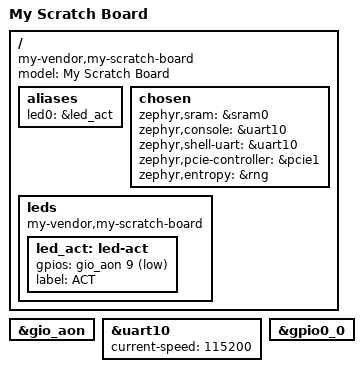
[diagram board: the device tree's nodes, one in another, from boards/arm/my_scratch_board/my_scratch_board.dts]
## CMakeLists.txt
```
cmake_minimum_required(VERSION 3.20)

set(DTS_ROOT ${CMAKE_CURRENT_SOURCE_DIR})
set(KCONFIG_ROOT ${CMAKE_CURRENT_SOURCE_DIR}/Kconfig.app)

find_package(Zephyr REQUIRED HINTS $ENV{ZEPHYR_BASE})
project(led_sensor_task2)

target_include_directories(app PRIVATE drivers/led_sensor)

target_sources(app PRIVATE
    src/main.c
    drivers/led_sensor/led_sensor.c
)
```

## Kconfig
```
source "Kconfig.zephyr"

mainmenu "LED Control Application"

menuconfig LED_SUBSYSTEM
    bool "LED Subsystem"
    default y

if LED_SUBSYSTEM

choice
    prompt "LED blink sleep time"
    default LED_BLINK_SLEEP_1S

    config LED_BLINK_SLEEP_250MS
        bool "250ms (fast)"
    config LED_BLINK_SLEEP_500MS
        bool "500ms (standard)"
    config LED_BLINK_SLEEP_1S
        bool "1s (medium)"
    config LED_BLINK_SLEEP_2S
        bool "2s (slow)"
endchoice

config LED_BLINK_TIME_MS
    int
    default 250 if LED_BLINK_SLEEP_250MS
    default 500 if LED_BLINK_SLEEP_500MS
    default 1000 if LED_BLINK_SLEEP_1S
    default 2000 if LED_BLINK_SLEEP_2S

menuconfig ADVANCED_LED_SETTINGS
    bool "Advanced LED settings"

if ADVANCED_LED_SETTINGS
    config LED_BRIGHTNESS
        int "LED brightness (0-100)"
        range 0 100
        default 100

    config LED_FADE_DURATION
        int "LED fade duration (ms)"
        range 0 5000
        default 500

    menu "Expert settings"
        visible if ADVANCED_LED_SETTINGS
        config ENABLE_LED_DEBUGGING
            bool "Enable LED debugging"
        config CUSTOM_BLINK_PATTERN
            bool "Custom blink pattern"
    endmenu
endif

endif

config APP_HEARTBEAT_PERIOD_MS
    int "Heartbeat LED period in milliseconds"
    default 500
    range 100 2000
    help
        Time between LED toggles (half period).
```

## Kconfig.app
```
source "$(APPLICATION_SOURCE_DIR)/drivers/led_sensor/Kconfig"
source "$(ZEPHYR_BASE)/Kconfig"
```

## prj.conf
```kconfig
CONFIG_MY_LED_SENSOR=y
CONFIG_GPIO=y
CONFIG_LOG=y
CONFIG_CONSOLE=y
CONFIG_SERIAL=y
CONFIG_UART_CONSOLE=y
```

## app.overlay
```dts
/ {
    my_led_sensor: my-led-sensor {
        compatible = "my-vendor,my-led-sensor";
        led-gpios = <&gio_aon 9 GPIO_ACTIVE_LOW>;
        status = "okay";
    };

    aliases {
        my-led-sensor = &my_led_sensor;
    };
};

/* Uses the activity LED on Raspberry Pi 5 (GPIO 9 via gio_aon) */
```

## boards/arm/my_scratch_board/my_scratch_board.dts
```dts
/*
 * Copyright 2024 Junho Lee <junho@tsnlab.com>
 *
 * SPDX-License-Identifier: Apache-2.0
 */

/dts-v1/;

#include <broadcom/bcm2712.dtsi>
#include <zephyr/dt-bindings/gpio/gpio.h>

/ {
	compatible = "my-vendor,my-scratch-board";
	model = "My Scratch Board";
	#address-cells = <2>;
	#size-cells = <1>;

	aliases {
		led0 = &led_act;
	};

	chosen {
		zephyr,sram = &sram0;
		zephyr,console = &uart10;
		zephyr,shell-uart = &uart10;
		zephyr,pcie-controller = &pcie1;
		zephyr,entropy = &rng;
	};

	leds {
		compatible = "my-vendor,my-scratch-board";

		led_act: led-act {
			gpios = <&gio_aon 9 GPIO_ACTIVE_LOW>;
			label = "ACT";
		};
	};
};

&gio_aon {
	status = "okay";
};

&uart10 {
	status = "okay";
	current-speed = <115200>;
};

&gpio0_0 {
	status = "okay";
};
```

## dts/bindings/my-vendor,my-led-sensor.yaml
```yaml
description: Simple on-board LED sensor driver

compatible: "my-vendor,my-led-sensor"

include: [sensor-device.yaml]

properties:
  led-gpios:
    type: phandle-array
    required: true
    description: GPIO pin connected to the LED
```

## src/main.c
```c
#include <zephyr/kernel.h>
#include <zephyr/device.h>
#include <zephyr/logging/log.h>
#include "led_sensor.h"

LOG_MODULE_REGISTER(main, LOG_LEVEL_INF);

int main(void)
{
    printk("=== Zephyr booted Task 2 ===\n");

    const struct device *sensor = DEVICE_DT_GET(DT_ALIAS(my_led_sensor));

    if (!device_is_ready(sensor)) {
        printk("ERROR: sensor not ready\n");
        return -ENODEV;
    }

    int val;

    LOG_INF("Round 1: default interval");
    led_sensor_fetch(sensor);
    led_sensor_get(sensor, &val);
    LOG_INF("Reported interval: %d ms", val);
    k_sleep(K_MSEC(500));

    led_sensor_set_interval(sensor, 200U);

    LOG_INF("Round 2: interval 200ms");
    led_sensor_fetch(sensor);
    led_sensor_get(sensor, &val);
    LOG_INF("Reported interval: %d ms", val);
    k_sleep(K_MSEC(500));

    led_sensor_set_interval(sensor, 1000U);

    LOG_INF("Round 3: interval 1000ms");
    led_sensor_fetch(sensor);
    led_sensor_get(sensor, &val);
    LOG_INF("Reported interval: %d ms", val);
    k_sleep(K_MSEC(500));

    LOG_INF("Task 2 complete");
    while (1) {
        k_sleep(K_MSEC(1000));
    }
    return 0;
}
```

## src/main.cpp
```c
#include <zephyr/drivers/gpio.h>
#include <zephyr/kernel.h>
#include <zephyr/logging/log.h>


/* The devicetree node identifier for the "led0" alias. */
#define LED_NODE DT_ALIAS(app_led)

static const struct gpio_dt_spec led = GPIO_DT_SPEC_GET(LED_NODE, gpios);

LOG_MODULE_REGISTER(main, LOG_LEVEL_INF);

int main(void)
{
    bool led_state = true;

    if (!gpio_is_ready_dt(&led)) return 0;

    if (gpio_pin_configure_dt(&led, GPIO_OUTPUT_ACTIVE) < 0) return 0;

    while (1) {
        if (gpio_pin_toggle_dt(&led) < 0) return 0;

        led_state = !led_state;
        LOG_INF("LED state: %s", led_state ? "ON" : "OFF");
        k_msleep(CONFIG_APP_HEARTBEAT_PERIOD_MS);
    }
    return 0;
}
```
